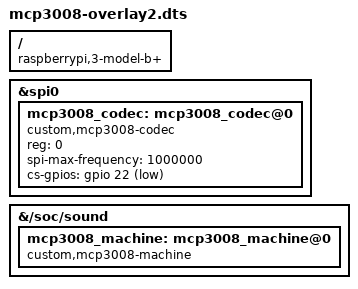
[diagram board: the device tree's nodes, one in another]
/dts-v1/;
/plugin/;

/ {
    compatible = "raspberrypi,3-model-b+";

    /* Fragment 0 : Configuration du périphérique SPI avec le codec */
    fragment@0 {
        target = <&spi0>;
        __overlay__ {
            status = "okay";
            mcp3008_codec: mcp3008_codec@0 {
                compatible = "custom,mcp3008-codec";
                reg = <0>;  /* 2 cellules pour l'adresse et 1 pour la taille */
                spi-max-frequency = <1000000>;
                cs-gpios = <&gpio 22 1>;
            };
        };
    };

    /* Fragment 1 : Définition du machine driver pour intégrer le codec à ALSA */
    fragment@1 {
        target-path = "/soc/sound";
        __overlay__ {
            status = "okay";
            mcp3008_machine: mcp3008_machine@0 {
                compatible = "custom,mcp3008-machine";
                status = "okay";
            };
        };
    };

};

